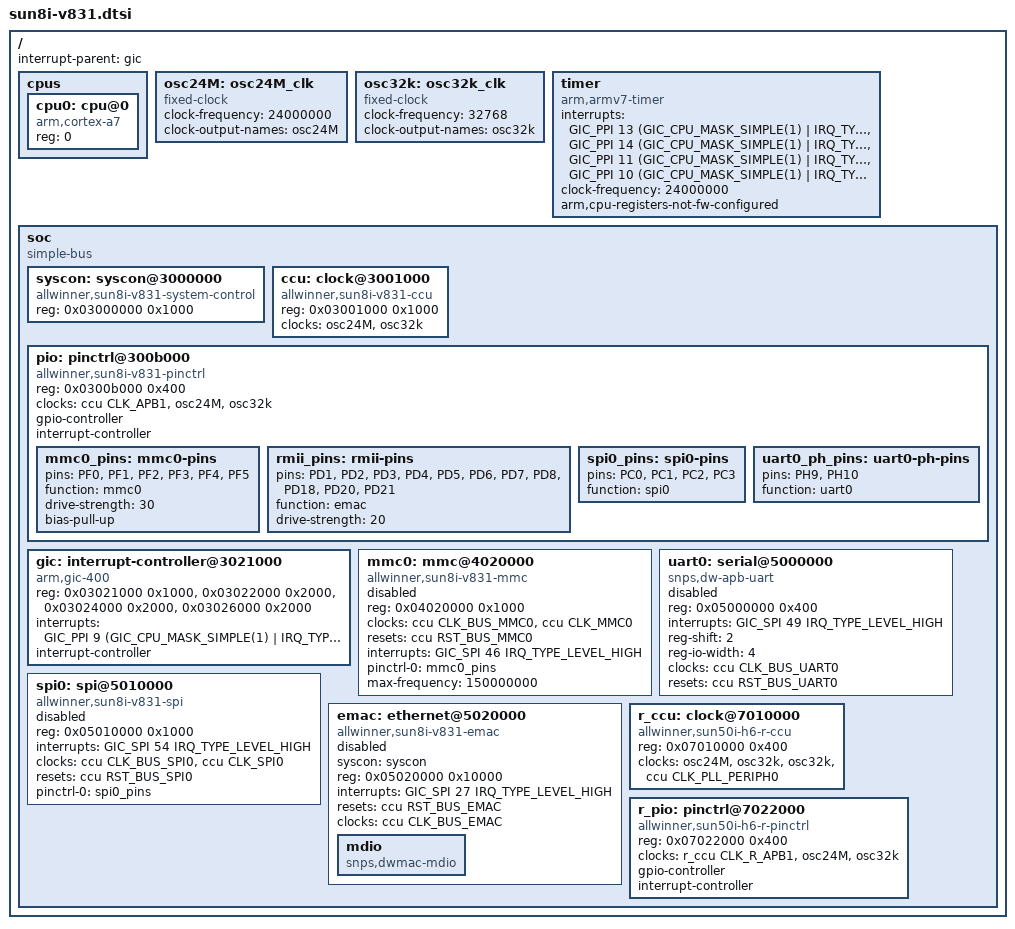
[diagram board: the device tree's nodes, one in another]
// SPDX-License-Identifier: (GPL-2.0+ OR MIT)
/*
 * Allwinner V831/V833 (sun8iw19p1): one Cortex-A7 with the H6's
 * peripherals, clocks and memory map. The clock and reset indices are the
 * H6's: the V831's CCU has the same bus gates at the same offsets (the
 * vendor kernel's clk-sun8iw19.h).
 */

#include <dt-bindings/interrupt-controller/arm-gic.h>
#include <dt-bindings/clock/sun50i-h6-ccu.h>
#include <dt-bindings/clock/sun50i-h6-r-ccu.h>
#include <dt-bindings/reset/sun50i-h6-ccu.h>
#include <dt-bindings/reset/sun50i-h6-r-ccu.h>

/ {
	interrupt-parent = <&gic>;
	#address-cells = <1>;
	#size-cells = <1>;

	cpus {
		#address-cells = <1>;
		#size-cells = <0>;

		cpu0: cpu@0 {
			compatible = "arm,cortex-a7";
			device_type = "cpu";
			reg = <0>;
		};
	};

	osc24M: osc24M_clk {
		#clock-cells = <0>;
		compatible = "fixed-clock";
		clock-frequency = <24000000>;
		clock-output-names = "osc24M";
	};

	osc32k: osc32k_clk {
		#clock-cells = <0>;
		compatible = "fixed-clock";
		clock-frequency = <32768>;
		clock-output-names = "osc32k";
	};

	timer {
		compatible = "arm,armv7-timer";
		interrupts = <GIC_PPI 13 (GIC_CPU_MASK_SIMPLE(1) | IRQ_TYPE_LEVEL_LOW)>,
			     <GIC_PPI 14 (GIC_CPU_MASK_SIMPLE(1) | IRQ_TYPE_LEVEL_LOW)>,
			     <GIC_PPI 11 (GIC_CPU_MASK_SIMPLE(1) | IRQ_TYPE_LEVEL_LOW)>,
			     <GIC_PPI 10 (GIC_CPU_MASK_SIMPLE(1) | IRQ_TYPE_LEVEL_LOW)>;
		clock-frequency = <24000000>;
		arm,cpu-registers-not-fw-configured;
	};

	soc {
		compatible = "simple-bus";
		#address-cells = <1>;
		#size-cells = <1>;
		ranges;

		syscon: syscon@3000000 {
			compatible = "allwinner,sun8i-v831-system-control",
				     "allwinner,sun50i-a64-system-control";
			reg = <0x03000000 0x1000>;
			#address-cells = <1>;
			#size-cells = <1>;
			ranges;
		};

		ccu: clock@3001000 {
			compatible = "allwinner,sun8i-v831-ccu";
			reg = <0x03001000 0x1000>;
			clocks = <&osc24M>, <&osc32k>;
			clock-names = "hosc", "losc";
			#clock-cells = <1>;
			#reset-cells = <1>;
		};

		pio: pinctrl@300b000 {
			compatible = "allwinner,sun8i-v831-pinctrl";
			reg = <0x0300b000 0x400>;
			clocks = <&ccu CLK_APB1>, <&osc24M>, <&osc32k>;
			clock-names = "apb", "hosc", "losc";
			gpio-controller;
			#gpio-cells = <3>;
			interrupt-controller;
			#interrupt-cells = <3>;

			mmc0_pins: mmc0-pins {
				pins = "PF0", "PF1", "PF2", "PF3", "PF4", "PF5";
				function = "mmc0";
				drive-strength = <30>;
				bias-pull-up;
			};

			rmii_pins: rmii-pins {
				pins = "PD1", "PD2", "PD3", "PD4", "PD5", "PD6",
				       "PD7", "PD8", "PD18", "PD20", "PD21";
				function = "emac";
				drive-strength = <20>;
			};

			spi0_pins: spi0-pins {
				pins = "PC0", "PC1", "PC2", "PC3";
				function = "spi0";
			};

			uart0_ph_pins: uart0-ph-pins {
				pins = "PH9", "PH10";
				function = "uart0";
			};
		};

		gic: interrupt-controller@3021000 {
			compatible = "arm,gic-400";
			reg = <0x03021000 0x1000>,
			      <0x03022000 0x2000>,
			      <0x03024000 0x2000>,
			      <0x03026000 0x2000>;
			interrupts = <GIC_PPI 9 (GIC_CPU_MASK_SIMPLE(1) | IRQ_TYPE_LEVEL_HIGH)>;
			interrupt-controller;
			#interrupt-cells = <3>;
		};

		mmc0: mmc@4020000 {
			compatible = "allwinner,sun8i-v831-mmc",
				     "allwinner,sun50i-h6-mmc";
			reg = <0x04020000 0x1000>;
			clocks = <&ccu CLK_BUS_MMC0>, <&ccu CLK_MMC0>;
			clock-names = "ahb", "mmc";
			resets = <&ccu RST_BUS_MMC0>;
			reset-names = "ahb";
			interrupts = <GIC_SPI 46 IRQ_TYPE_LEVEL_HIGH>;
			pinctrl-names = "default";
			pinctrl-0 = <&mmc0_pins>;
			max-frequency = <150000000>;
			status = "disabled";
			#address-cells = <1>;
			#size-cells = <0>;
		};

		uart0: serial@5000000 {
			compatible = "snps,dw-apb-uart";
			reg = <0x05000000 0x400>;
			interrupts = <GIC_SPI 49 IRQ_TYPE_LEVEL_HIGH>;
			reg-shift = <2>;
			reg-io-width = <4>;
			clocks = <&ccu CLK_BUS_UART0>;
			resets = <&ccu RST_BUS_UART0>;
			status = "disabled";
		};

		spi0: spi@5010000 {
			compatible = "allwinner,sun8i-v831-spi",
				     "allwinner,sun8i-h3-spi";
			reg = <0x05010000 0x1000>;
			interrupts = <GIC_SPI 54 IRQ_TYPE_LEVEL_HIGH>;
			clocks = <&ccu CLK_BUS_SPI0>, <&ccu CLK_SPI0>;
			clock-names = "ahb", "mod";
			resets = <&ccu RST_BUS_SPI0>;
			pinctrl-names = "default";
			pinctrl-0 = <&spi0_pins>;
			status = "disabled";
			#address-cells = <1>;
			#size-cells = <0>;
		};

		emac: ethernet@5020000 {
			compatible = "allwinner,sun8i-v831-emac",
				     "allwinner,sun50i-a64-emac";
			syscon = <&syscon>;
			reg = <0x05020000 0x10000>;
			interrupts = <GIC_SPI 27 IRQ_TYPE_LEVEL_HIGH>;
			interrupt-names = "macirq";
			resets = <&ccu RST_BUS_EMAC>;
			reset-names = "stmmaceth";
			clocks = <&ccu CLK_BUS_EMAC>;
			clock-names = "stmmaceth";
			status = "disabled";

			mdio: mdio {
				compatible = "snps,dwmac-mdio";
				#address-cells = <1>;
				#size-cells = <0>;
			};
		};

		r_ccu: clock@7010000 {
			compatible = "allwinner,sun50i-h6-r-ccu";
			reg = <0x07010000 0x400>;
			clocks = <&osc24M>, <&osc32k>, <&osc32k>,
				 <&ccu CLK_PLL_PERIPH0>;
			clock-names = "hosc", "losc", "iosc", "pll-periph";
			#clock-cells = <1>;
			#reset-cells = <1>;
		};

		r_pio: pinctrl@7022000 {
			compatible = "allwinner,sun50i-h6-r-pinctrl";
			reg = <0x07022000 0x400>;
			clocks = <&r_ccu CLK_R_APB1>, <&osc24M>, <&osc32k>;
			clock-names = "apb", "hosc", "losc";
			gpio-controller;
			#gpio-cells = <3>;
			interrupt-controller;
			#interrupt-cells = <3>;
		};
	};
};
